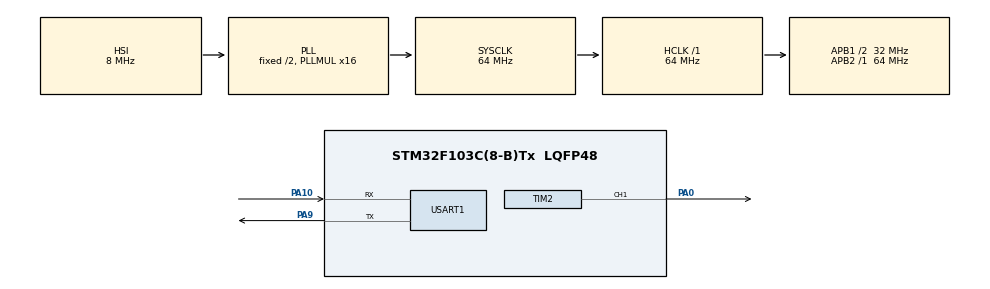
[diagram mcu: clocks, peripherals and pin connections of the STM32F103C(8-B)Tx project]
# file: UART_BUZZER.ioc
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Mcu.Family=STM32F1
Mcu.Name=STM32F103C(8-B)Tx
Mcu.Package=LQFP48
NVIC.PriorityGroup=NVIC_PRIORITYGROUP_4
PA0-WKUP.Signal=S_TIM2_CH1_ETR
PA10.Mode=Asynchronous
PA10.Signal=USART1_RX
PA9.Mode=Asynchronous
PA9.Signal=USART1_TX
ProjectManager.HeapSize=0x200
ProjectManager.StackSize=0x400
ProjectManager.TargetToolchain=STM32CubeIDE
RCC.AHBFreq_Value=64000000
RCC.APB1CLKDivider=RCC_HCLK_DIV2
RCC.APB1Freq_Value=32000000
RCC.APB1TimFreq_Value=64000000
RCC.APB2Freq_Value=64000000
RCC.APB2TimFreq_Value=64000000
RCC.HCLKFreq_Value=64000000
RCC.PLLMUL=RCC_PLL_MUL16
RCC.SYSCLKFreq_VALUE=64000000
RCC.SYSCLKSource=RCC_SYSCLKSOURCE_PLLCLK
RCC.USBFreq_Value=64000000
SH.S_TIM2_CH1_ETR.0=TIM2_CH1,PWM Generation1 CH1
TIM2.Channel-PWM\ Generation1\ CH1=TIM_CHANNEL_1
TIM2.Prescaler=63
USART1.VirtualMode=VM_ASYNC
VP_SYS_VS_ND.Mode=No_Debug
board=custom

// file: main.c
/* USER CODE BEGIN Header */
/**
  ******************************************************************************
  * @file           : main.c
  * @brief          : Main program body
  ******************************************************************************
  * @attention
  *
  * Copyright (c) 2026 STMicroelectronics.
  * All rights reserved.
  *
  * This software is licensed under terms that can be found in the LICENSE file
  * in the root directory of this software component.
  * If no LICENSE file comes with this software, it is provided AS-IS.
  *
  ******************************************************************************
  */
/* USER CODE END Header */
#include "main.h"
#include "tim.h"
#include "usart.h"
#include "gpio.h"

/* USER CODE BEGIN Includes */
#include <stdio.h>
/* USER CODE END Includes */

void SystemClock_Config(void);

/* USER CODE BEGIN 0 */
int _write(int file, char *ptr, int len)
{
  HAL_UART_Transmit(&huart1, (uint8_t*)ptr, len, HAL_MAX_DELAY);
  return len;
}

int _read(int file, char *ptr, int len) { return 0; }
int _close(int file) { return -1; }
int _lseek(int file, int ptr, int dir) { return 0; }
int _fstat(int file, void *st) { return 0; }
int _isatty(int file) { return 1; }
void *_sbrk(int incr) { return (void *)-1; }
/* USER CODE END 0 */

int main(void)
{

  /* MCU Configuration--------------------------------------------------------*/

  /* Reset of all peripherals, Initializes the Flash interface and the Systick. */
  HAL_Init();

  /* Configure the system clock */
  SystemClock_Config();

  /* Initialize all configured peripherals */
  MX_GPIO_Init();
  MX_TIM2_Init();
  MX_USART1_UART_Init();
  /* USER CODE BEGIN 2 */
  printf("Sistem baslatildi\r\n");
  HAL_TIM_PWM_Start(&htim2, TIM_CHANNEL_1);
  /* USER CODE END 2 */

  /* Infinite loop */
  while (1)
  {
	  __HAL_TIM_SET_AUTORELOAD(&htim2, 999);
	  __HAL_TIM_SET_COMPARE(&htim2, TIM_CHANNEL_1, 499);
	  printf("[BIP 1] 1000 Hz\r\n");
	  HAL_Delay(300);

	  __HAL_TIM_SET_COMPARE(&htim2, TIM_CHANNEL_1, 0);
	  HAL_Delay(200);

	  __HAL_TIM_SET_AUTORELOAD(&htim2, 499);
	  __HAL_TIM_SET_COMPARE(&htim2, TIM_CHANNEL_1, 249);
	  printf("[BIP 2] 2000 Hz\r\n");
	  HAL_Delay(300);

	  __HAL_TIM_SET_COMPARE(&htim2, TIM_CHANNEL_1, 0);
	  HAL_Delay(200);

	  __HAL_TIM_SET_AUTORELOAD(&htim2, 1999);
	  __HAL_TIM_SET_COMPARE(&htim2, TIM_CHANNEL_1, 999);
	  printf("[BIP 3] 500 Hz\r\n");
	  HAL_Delay(300);

	  __HAL_TIM_SET_COMPARE(&htim2, TIM_CHANNEL_1, 0);
	  HAL_Delay(500);
  }
}

void SystemClock_Config(void)
{
  RCC_OscInitTypeDef RCC_OscInitStruct = {0};
  RCC_ClkInitTypeDef RCC_ClkInitStruct = {0};

  /** Initializes the RCC Oscillators according to the specified parameters
  * in the RCC_OscInitTypeDef structure.
  */
  RCC_OscInitStruct.OscillatorType = RCC_OSCILLATORTYPE_HSI;
  RCC_OscInitStruct.HSIState = RCC_HSI_ON;
  RCC_OscInitStruct.HSICalibrationValue = RCC_HSICALIBRATION_DEFAULT;
  RCC_OscInitStruct.PLL.PLLState = RCC_PLL_ON;
  RCC_OscInitStruct.PLL.PLLSource = RCC_PLLSOURCE_HSI_DIV2;
  RCC_OscInitStruct.PLL.PLLMUL = RCC_PLL_MUL16;
  if (HAL_RCC_OscConfig(&RCC_OscInitStruct) != HAL_OK)
  {
    Error_Handler();
  }

  /** Initializes the CPU, AHB and APB buses clocks
  */
  RCC_ClkInitStruct.ClockType = RCC_CLOCKTYPE_HCLK|RCC_CLOCKTYPE_SYSCLK
                              |RCC_CLOCKTYPE_PCLK1|RCC_CLOCKTYPE_PCLK2;
  RCC_ClkInitStruct.SYSCLKSource = RCC_SYSCLKSOURCE_PLLCLK;
  RCC_ClkInitStruct.AHBCLKDivider = RCC_SYSCLK_DIV1;
  RCC_ClkInitStruct.APB1CLKDivider = RCC_HCLK_DIV2;
  RCC_ClkInitStruct.APB2CLKDivider = RCC_HCLK_DIV1;

  if (HAL_RCC_ClockConfig(&RCC_ClkInitStruct, FLASH_LATENCY_2) != HAL_OK)
  {
    Error_Handler();
  }
}

void Error_Handler(void)
{
  __disable_irq();
  while (1)
  {
  }
}
